# f2838x_flash_ctrl_regs register map
Vendor: Texas Instruments
Peripheral module from a debugger description file (folder C2000).
Address unit: 16 bits
Registers are 32-bit, read-write, no defined reset value unless marked. A register's access mark holds for its fields unless they carry their own. Offsets are as the file gives them; lines under a group give offsets from that group; [hi:lo] are bit positions; {n}, {i} and the like mark numbered series; 'fields as' and 'values as' point back to an identical list; <NAME> marks a mode.

## FLASH_CTRL_REGS — FLASH CTRL Registers
0x00 FRDCNTL — Flash Read Control Register
  [11:8] RWAIT — Random Read Waitstate
0x1E FBAC — Flash Bank Access Control Register
  [7:0] VREADST — VREAD Setup Time Count
0x20 FBFALLBACK — Flash Bank Fallback Power Register
  [1:0] BNKPWR0 — Bank Power Mode
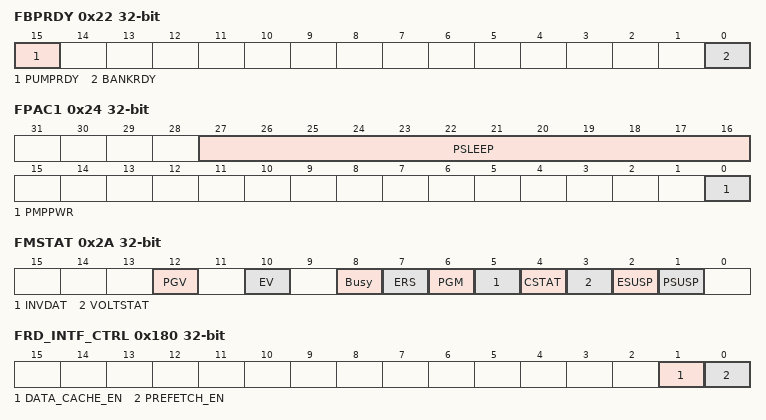
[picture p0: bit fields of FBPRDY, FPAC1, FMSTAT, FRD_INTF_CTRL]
0x22 FBPRDY ro — Flash Bank Pump Ready Register
  [15] PUMPRDY — Flash Pump Active Power Mode
  [0] BANKRDY — Flash Bank Active Power State
0x24 FPAC1 — Flash Pump Access Control Register 1
  [27:16] PSLEEP — Pump Sleep Down Count
  [0] PMPPWR — Charge Pump Fallback Power Mode
0x2A FMSTAT ro — Flash Module Status Register
  [12] PGV — Program verify
  [10] EV — Erase verify
  [8] Busy — Busy Bit.
  [7] ERS — Erase Active.
  [6] PGM — Program Active.
  [5] INVDAT — Invalid Data.
  [4] CSTAT — Command Status.
  [3] VOLTSTAT — Core Voltage Status.
  [2] ESUSP — Erase Suspend.
  [1] PSUSP — Program Suspend.
0x180 FRD_INTF_CTRL — Flash Read Interface Control Register
  [1] DATA_CACHE_EN — Data Cache Enable
  [0] PREFETCH_EN — Prefetch Enable
